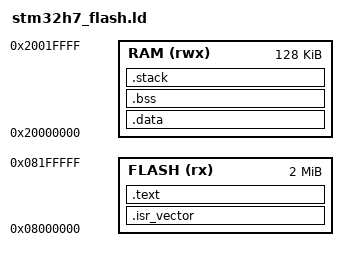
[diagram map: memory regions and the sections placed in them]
MEMORY
{
  FLASH (rx)  : ORIGIN = 0x08000000, LENGTH = 2048K
  RAM   (rwx) : ORIGIN = 0x20000000, LENGTH = 128K
}

ENTRY(Reset_Handler)

SECTIONS
{
  .isr_vector :
  {
    KEEP(*(.isr_vector))
  } > FLASH

  .text :
  {
    *(.text*)
    *(.rodata*)
    KEEP(*(.init))
    KEEP(*(.fini))
    . = ALIGN(4);
    _etext = .;
  } > FLASH

  .data : AT(_etext)
  {
    . = ALIGN(4);
    _sdata = .;
    *(.data*)
    . = ALIGN(4);
    _edata = .;
  } > RAM

  .bss :
  {
    . = ALIGN(4);
    _sbss = .;
    *(.bss*)
    *(COMMON)
    . = ALIGN(4);
    _ebss = .;
  } > RAM

  .stack (NOLOAD):
  {
    . = ALIGN(8);
    _sstack = .;
    . = . + 0x2000;
    . = ALIGN(8);
    _estack = .;
  } > RAM
}
